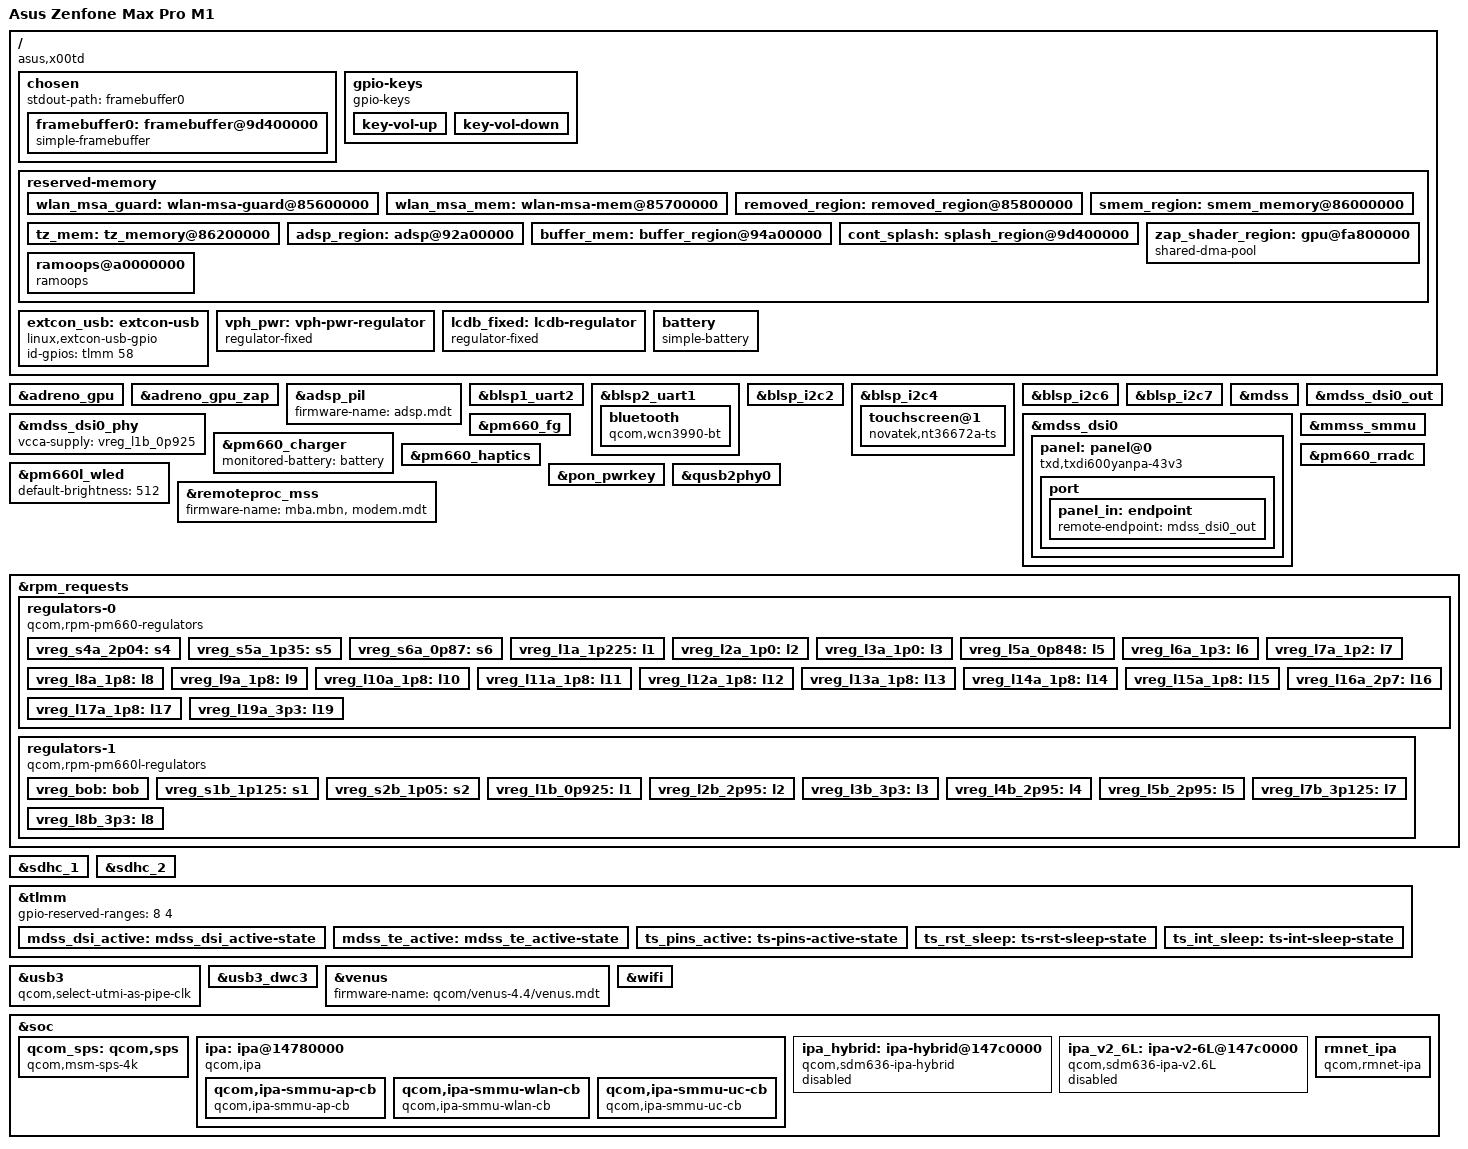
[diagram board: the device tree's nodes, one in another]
// SPDX-License-Identifier: GPL-2.0-only
/*
 * Copyright (c) 2022, Aboothahir U <aboothahirpkd@gmail.com>
 */

/dts-v1/;

#include "sdm636.dtsi"
#include "pm660.dtsi"
#include "pm660l.dtsi"
#include <dt-bindings/input/input.h>
#include <dt-bindings/input/gpio-keys.h>

/delete-node/ &qhee_code;
/delete-node/ &smem_region;
/delete-node/ &tz_mem;
/delete-node/ &adsp_region;
/delete-node/ &buffer_mem;
/delete-node/ &zap_shader_region;

/ {
	model = "Asus Zenfone Max Pro M1";
	compatible = "asus,x00td", "qcom,sdm636";
	chassis-type = "handset";

	qcom,msm-id = <0x159 0x0>;
	qcom,board-id = <0x1000b 0x0>;
	qcom,pmic-id = <0x1001b 0x101011a 0x0 0x0 0x1001b 0x201011a 0x0 0x0 0x1001b 0x102001a 0x0 0x0>;

	chosen {
		#address-cells = <2>;
		#size-cells = <2>;
		ranges;

		stdout-path = "framebuffer0";

		framebuffer0: framebuffer@9d400000 {
			compatible = "simple-framebuffer";
			reg = <0x0 0x9d400000 0x0 (1080 * 2160 * 4)>;
			status = "okay";
			width = <1080>;
			height = <2160>;
			stride = <(1080 * 4)>;
			format = "a8r8g8b8";
		};
	};

	gpio-keys {
		status = "okay";
		compatible = "gpio-keys";

		key-vol-up {
			label = "Volume Up";
			gpios = <&tlmm 44 GPIO_ACTIVE_LOW>;
			linux,input-type = <1>;
			linux,code = <KEY_VOLUMEUP>;
			wakeup-source;
			debounce-interval = <15>;
		};

		key-vol-down {
			label = "Volume Down";
			gpios = <&tlmm 43 GPIO_ACTIVE_LOW>;
			linux,input-type = <1>;
			linux,code = <KEY_VOLUMEDOWN>;
			wakeup-source;
			debounce-interval = <15>;
		};
	};

	reserved-memory {
		#address-cells = <2>;
		#size-cells = <2>;
		ranges;
		wlan_msa_guard: wlan-msa-guard@85600000 {
			reg = <0x0 0x85600000 0x0 0x100000>;
			no-map;
		};

		wlan_msa_mem: wlan-msa-mem@85700000 {
			reg = <0x0 0x85700000 0x0 0x100000>;
			no-map;
		};

		/* removed_regions in downstream / qhee_code */
		removed_region: removed_region@85800000 {
			reg = <0x0 0x85800000 0x0 0x600000>;
			no-map;
		};

		smem_region: smem_memory@86000000 {
			reg = <0x0 0x86000000 0x0 0x200000>;
			no-map;
		};

		/* tz_mem */
		tz_mem: tz_memory@86200000 {
			reg = <0x0 0x86200000 0x0 0x2D00000>;
			/* 0x86200000 + 0x2D00000 = 0x88F00000 */
			no-map;
		};

		/* adsp_fw_region */
		adsp_region: adsp@92a00000 {
			reg = <0x0 0x92a00000 0x0 0x1e00000>;
			no-map;
		};

		/* cdsp_fw_region */
		buffer_mem: buffer_region@94a00000 {
			reg = <0x0 0x94a00000 0x0 0x600000>;
			no-map;
		};

		/* cont_splash_region / framebuffer */
		cont_splash: splash_region@9d400000 {
			reg = <0x0 0x9d400000 0x0 0x2400000>;
			no-map;
		};

		zap_shader_region: gpu@fa800000 {
			compatible = "shared-dma-pool";
			reg = <0x0 0xfa800000 0x0 0x2000>;
			no-map;
		};

		ramoops@a0000000 {
			compatible = "ramoops";
			reg = <0x0 0xa0000000 0x0 0x400000>;
			console-size = <0x20000>;
			record-size = <0x20000>;
			ftrace-size = <0x0>;
			pmsg-size = <0x20000>;
		};
	};
	
	/*
	 * Until we hook up type-c detection, we
	 * have to stick with this. But it works.
	 */
	extcon_usb: extcon-usb {
		compatible = "linux,extcon-usb-gpio";
		id-gpios = <&tlmm 58 GPIO_ACTIVE_HIGH>;
	};

	vph_pwr: vph-pwr-regulator {
		compatible = "regulator-fixed";
		regulator-name = "vph_pwr";
		regulator-min-microvolt = <3700000>;
		regulator-max-microvolt = <3700000>;
		regulator-always-on;
		regulator-boot-on;
	};

	/*
	 * This is here until we have a driver for QPNP LCDB regulator.
	 * It can emulate both positive LDO and negative NCP supplies for panel.
	 */
	lcdb_fixed: lcdb-regulator {
		compatible = "regulator-fixed";
		regulator-name = "lcdb";
		/*
		 * Actual range for LCDB is 4.0 - 6.0V, but
		 * stock bootloader sets voltage to 5.4 V
		 */
		regulator-min-microvolt = <5400000>;
		regulator-max-microvolt = <5400000>;
		regulator-always-on;
		regulator-boot-on;
	};

	battery: battery {
			compatible = "simple-battery";

			charge-full-design-microamp-hours = <5000000>;
			voltage-min-design-microvolt = <3400000>;
			voltage-max-design-microvolt = <4350000>;
	};
};

&adreno_gpu {
	status = "okay";
};

&adreno_gpu_zap {
	memory-region = <&zap_shader_region>;
	firmware-name = "a512_zap.mbn";
};

&adsp_pil {
	firmware-name = "adsp.mdt";
};

&blsp1_uart2 {
	status = "okay";
};

&blsp2_uart1 {
	status = "okay";

	/* HCI Bluetooth */
	bluetooth {
		compatible = "qcom,wcn3990-bt";
		vddxo-supply = <&vreg_l9a_1p8>;
		vddrf-supply = <&vreg_l6a_1p3>;
		vddch0-supply = <&vreg_l19a_3p3>;
		vddio-supply = <&vreg_l13a_1p8>;
		max-speed = <3200000>;
	};
};

&blsp_i2c2 {
	status = "okay";
};

&blsp_i2c4 {
	#address-cells = <1>;
	#size-cells = <0>;

	status = "okay";

	touchscreen@1 {
		compatible = "novatek,nt36672a-ts";
		reg = <0x1>;
		iovcc-supply = <&vreg_l11a_1p8>;
		interrupts-extended = <&tlmm 67 IRQ_TYPE_EDGE_RISING>;
		pinctrl-names = "default", "sleep";
		pinctrl-0 = <&ts_pins_active>;
		pinctrl-1 = <&ts_int_sleep &ts_rst_sleep>;
		reset-gpios = <&tlmm 66 GPIO_ACTIVE_LOW>;
		touchscreen-size-x = <1080>;
		touchscreen-size-y = <2160>;
	};
};

&blsp_i2c6 {
	status = "okay";

	/* tfa98xx@34 */
};

&blsp_i2c7 { /* for P/L Sensor */
	status = "okay";
};

&mdss {
	status = "okay";
};

&mdss_dsi0 {
	status = "okay";

	#address-cells = <1>;
	#size-cells = <0>;

	vdd-supply = <&vreg_l1b_0p925>;
	vdda-supply = <&vreg_l1a_1p225>;

	panel: panel@0 {
		reg = <0>;
		compatible = "txd,txdi600yanpa-43v3", "novatek,nt36672a";

		vddio-supply = <&vreg_l11a_1p8>;
		vddneg-supply = <&lcdb_fixed>;
		vddpos-supply = <&lcdb_fixed>;

		backlight = <&pm660l_wled>;

		reset-gpios = <&tlmm 53 GPIO_ACTIVE_LOW>;

		pinctrl-names = "default";
		pinctrl-0 = <&mdss_dsi_active &mdss_te_active>;

		port {
			panel_in: endpoint {
				remote-endpoint = <&mdss_dsi0_out>;
			};
		};
	};
};

&mdss_dsi0_out {
	data-lanes = <0 1 2 3>;
	remote-endpoint = <&panel_in>;
};

&mdss_dsi0_phy {
	vcca-supply = <&vreg_l1b_0p925>;

	status = "okay";
};

&mmss_smmu {
	status = "okay";
};

&pm660_charger {
	monitored-battery = <&battery>;

	status = "okay";
};

&pm660_fg {
	monitored-battery = <&battery>;
	power-supplies = <&pm660_charger>;

	status = "okay";
};

&pm660_haptics {
	status = "okay";
};

&pm660_rradc {
	status = "okay";
};

&pm660l_wled {
	default-brightness = <512>;

	status = "okay";
};

&pon_pwrkey {
	status = "okay";
};

&qusb2phy0 {
	vdd-supply = <&vreg_l1b_0p925>;
	vdda-pll-supply = <&vreg_l10a_1p8>;
	vdda-phy-dpdm-supply = <&vreg_l7b_3p125>;

	status = "okay";
};

&remoteproc_mss {
	firmware-name = "mba.mbn", "modem.mdt";

	status = "okay";
};

&rpm_requests {
	regulators-0 {
		compatible = "qcom,rpm-pm660-regulators";

		vdd_s1-supply = <&vph_pwr>;
		vdd_s2-supply = <&vph_pwr>;
		vdd_s3-supply = <&vph_pwr>;
		vdd_s4-supply = <&vph_pwr>;
		vdd_s5-supply = <&vph_pwr>;
		vdd_s6-supply = <&vph_pwr>;

		vdd_l1_l6_l7-supply = <&vreg_s5a_1p35>;
		vdd_l2_l3-supply = <&vreg_s2b_1p05>;
		vdd_l5-supply = <&vreg_s2b_1p05>;
		vdd_l8_l9_l10_l11_l12_l13_l14-supply = <&vreg_s4a_2p04>;
		vdd_l15_l16_l17_l18_l19-supply = <&vreg_bob>;

		/*
		 * S1A (FTAPC0), S2A (FTAPC1), S3A (HFAPC1) are managed
		 * by the Core Power Reduction hardened (CPRh) and the
		 * Operating State Manager (OSM) HW automatically.
		 */

		vreg_s4a_2p04: s4 {
			regulator-min-microvolt = <1805000>;
			regulator-max-microvolt = <2040000>;
			regulator-enable-ramp-delay = <200>;
			regulator-always-on;
		};

		vreg_s5a_1p35: s5 {
			regulator-min-microvolt = <1224000>;
			regulator-max-microvolt = <1350000>;
			regulator-enable-ramp-delay = <200>;
		};

		vreg_s6a_0p87: s6 {
			regulator-min-microvolt = <504000>;
			regulator-max-microvolt = <992000>;
			regulator-enable-ramp-delay = <150>;
		};

		/* LDOs */
		vreg_l1a_1p225: l1 {
			regulator-min-microvolt = <1150000>;
			regulator-max-microvolt = <1250000>;
			regulator-enable-ramp-delay = <250>;
			regulator-allow-set-load;
		};

		vreg_l2a_1p0: l2 {
			regulator-min-microvolt = <950000>;
			regulator-max-microvolt = <1010000>;
			regulator-enable-ramp-delay = <250>;
		};

		vreg_l3a_1p0: l3 {
			regulator-min-microvolt = <950000>;
			regulator-max-microvolt = <1010000>;
			regulator-enable-ramp-delay = <250>;
		};

		vreg_l5a_0p848: l5 {
			regulator-min-microvolt = <525000>;
			regulator-max-microvolt = <950000>;
			regulator-enable-ramp-delay = <250>;
		};

		vreg_l6a_1p3: l6 {
			regulator-min-microvolt = <1200000>;
			regulator-max-microvolt = <1370000>;
			regulator-allow-set-load;
			regulator-enable-ramp-delay = <250>;
		};

		vreg_l7a_1p2: l7 {
			regulator-min-microvolt = <1200000>;
			regulator-max-microvolt = <1200000>;
			regulator-enable-ramp-delay = <250>;
            regulator-always-on;
		};

		vreg_l8a_1p8: l8 {
			regulator-min-microvolt = <1750000>;
			regulator-max-microvolt = <1800000>;
			regulator-enable-ramp-delay = <250>;
			regulator-system-load = <325000>;
			regulator-allow-set-load;
		};

		vreg_l9a_1p8: l9 {
			regulator-min-microvolt = <1750000>;
			regulator-max-microvolt = <1900000>;
			regulator-enable-ramp-delay = <250>;
			regulator-allow-set-load;
		};

		vreg_l10a_1p8: l10 {
			regulator-min-microvolt = <1780000>;
			regulator-max-microvolt = <1950000>;
			regulator-enable-ramp-delay = <250>;
			regulator-allow-set-load;
		};

		vreg_l11a_1p8: l11 {
			regulator-min-microvolt = <1780000>;
			regulator-max-microvolt = <1950000>;
			regulator-enable-ramp-delay = <250>;
		};

		vreg_l12a_1p8: l12 {
			regulator-min-microvolt = <1780000>;
			regulator-max-microvolt = <1950000>;
			regulator-enable-ramp-delay = <250>;
		};

		/* This gives power to the LPDDR4: never turn it off! */
		vreg_l13a_1p8: l13 {
			regulator-min-microvolt = <1780000>;
			regulator-max-microvolt = <1950000>;
			regulator-enable-ramp-delay = <250>;
			regulator-boot-on;
			regulator-always-on;
		};

		vreg_l14a_1p8: l14 {
			regulator-min-microvolt = <1710000>;
			regulator-max-microvolt = <1900000>;
			regulator-enable-ramp-delay = <250>;
		};

		vreg_l15a_1p8: l15 {
			regulator-min-microvolt = <1650000>;
			regulator-max-microvolt = <2950000>;
			regulator-enable-ramp-delay = <250>;
		};

		vreg_l16a_2p7: l16 {
			regulator-min-microvolt = <2800000>;
			regulator-max-microvolt = <2800000>;
			regulator-enable-ramp-delay = <250>;
			regulator-always-on;
		};

		vreg_l17a_1p8: l17 {
			regulator-min-microvolt = <1648000>;
			regulator-max-microvolt = <2952000>;
			regulator-enable-ramp-delay = <250>;
		};

		vreg_l19a_3p3: l19 {
			regulator-min-microvolt = <3312000>;
			regulator-max-microvolt = <3400000>;
			regulator-enable-ramp-delay = <250>;
			regulator-allow-set-load;
		};
	};

	regulators-1 {
		compatible = "qcom,rpm-pm660l-regulators";

		vdd_s1-supply = <&vph_pwr>;
		vdd_s2-supply = <&vph_pwr>;
		vdd_s3_s4-supply = <&vph_pwr>;
		vdd_s5-supply = <&vph_pwr>;
		vdd_s6-supply = <&vph_pwr>;

		vdd_l1_l9_l10-supply = <&vreg_s2b_1p05>;
		vdd_l2-supply = <&vreg_bob>;
		vdd_l3_l5_l7_l8-supply = <&vreg_bob>;
		vdd_l4_l6-supply = <&vreg_bob>;
		vdd_bob-supply = <&vph_pwr>;

		vreg_bob: bob {
			regulator-min-microvolt = <3300000>;
			regulator-max-microvolt = <3600000>;
			regulator-enable-ramp-delay = <500>;
		};

		vreg_s1b_1p125: s1 {
			regulator-min-microvolt = <1125000>;
			regulator-max-microvolt = <1125000>;
			regulator-enable-ramp-delay = <200>;
		};

		vreg_s2b_1p05: s2 {
			regulator-min-microvolt = <1050000>;
			regulator-max-microvolt = <1050000>;
			regulator-enable-ramp-delay = <200>;
		};

		/* LDOs */
		vreg_l1b_0p925: l1 {
			regulator-min-microvolt = <800000>;
			regulator-max-microvolt = <925000>;
			regulator-enable-ramp-delay = <250>;
			regulator-allow-set-load;
		};

		/* SDHCI 3.3V signal doesn't seem to be supported. */
		vreg_l2b_2p95: l2 {
			regulator-min-microvolt = <1648000>;
			regulator-max-microvolt = <3100000>;
			regulator-enable-ramp-delay = <250>;
			regulator-allow-set-load;
		};

		vreg_l3b_3p3: l3 {
			regulator-min-microvolt = <1700000>;
			regulator-max-microvolt = <3300000>;
			regulator-enable-ramp-delay = <250>;
			regulator-allow-set-load;
			regulator-always-on;
		};

		vreg_l4b_2p95: l4 {
			regulator-min-microvolt = <2944000>;
			regulator-max-microvolt = <2952000>;
			regulator-enable-ramp-delay = <250>;

			regulator-min-microamp = <200>;
			regulator-max-microamp = <600000>;
			regulator-system-load = <570000>;
			regulator-allow-set-load;
		};

		/*
		 * Downstream specifies a range of 1721-3600mV,
		 * but the only assigned consumers are SDHCI2 VMMC
		 * and Coresight QPDI that both request pinned 2.95V.
		 * Tighten the range to 1.8-3.328 (closest to 3.3) to
		 * make the mmc driver happy.
		 */
		vreg_l5b_2p95: l5 {
			regulator-min-microvolt = <1800000>;
			regulator-max-microvolt = <3328000>;
			regulator-enable-ramp-delay = <250>;
			regulator-allow-set-load;
		};

		vreg_l7b_3p125: l7 {
			regulator-min-microvolt = <2700000>;
			regulator-max-microvolt = <3125000>;
			regulator-enable-ramp-delay = <250>;
		};

		vreg_l8b_3p3: l8 {
			regulator-min-microvolt = <3200000>;
			regulator-max-microvolt = <3400000>;
			regulator-enable-ramp-delay = <250>;
		};
	};
};

&sdhc_1 {
	bus-width = <8>;
	non-removable;
	mmc-ddr-1_8v;    
	mmc-hs200-1_8v;  
	mmc-hs400-1_8v; 
	vmmc-supply = <&vreg_l4b_2p95>;
	vqmmc-supply = <&vreg_l8a_1p8>;

	status = "okay";
};


&sdhc_2 {
	cd-gpios = <&tlmm 54 GPIO_ACTIVE_HIGH>;

	vmmc-supply = <&vreg_l5b_2p95>;
	vqmmc-supply = <&vreg_l2b_2p95>;

	status = "okay";
};

&tlmm {
	gpio-reserved-ranges = <8 4>;

	mdss_dsi_active: mdss_dsi_active-state {
		function = "gpio";
		pins = "gpio53";
		drive-strength = <8>;
		bias-disable;
	};

	mdss_te_active: mdss_te_active-state {
		pins = "gpio59";
		function = "mdp_vsync";
		drive-strength = <2>;
		bias-pull-down;
	};

	ts_pins_active: ts-pins-active-state {
		pins = "gpio66", "gpio67";
		function = "gpio";
		drive-strength = <16>;
		bias-pull-up;
	};

	ts_rst_sleep: ts-rst-sleep-state {
		pins = "gpio66";
		function = "gpio";
		drive-strength = <2>;
		bias-pull-down;
	};

	ts_int_sleep: ts-int-sleep-state {
		pins = "gpio67";
		function = "gpio";
		drive-strength = <2>;
		bias-disable;
	};
};

&usb3 {
	qcom,select-utmi-as-pipe-clk;

	status = "okay";
};

&usb3_dwc3 {
	dr_mode = "peripheral";
	extcon = <&extcon_usb>;

	maximum-speed = "high-speed";
	phys = <&qusb2phy0>;
	phy-names = "usb2-phy";

	status = "okay";
};

&venus {
	firmware-name = "qcom/venus-4.4/venus.mdt";

	status = "okay";
};

&wifi {
	vdd-1.8-xo-supply = <&vreg_l9a_1p8>;
	vdd-1.3-rfa-supply = <&vreg_l6a_1p3>;
	vdd-3.3-ch0-supply = <&vreg_l19a_3p3>;

	status = "okay";
};

&soc {
    qcom_sps: qcom,sps {
		compatible = "qcom,msm-sps-4k";
		qcom,device-type = <3>;     /* default value — no BAMDMA */
		qcom,pipe-attr-ee;
		status = "okay";
	};

	/* IPA hardware (chip core + BAM-DMA at +0x4000) */
	ipa: ipa@14780000 {
		compatible = "qcom,ipa";

		/* Two separate register ranges: IPA core + BAM-DMA */
		reg = <0x14780000 0x4000>,
		      <0x14784000 0x3C000>;
		reg-names = "ipa-base", "bam-base";

		qcom,ipa-hw-ver = <6>;
		qcom,ipa-hw-mode = <0>;            /* IPA_MODE_NORMAL */
		qcom,ee = <0>;
		qcom,wan-rx-ring-size = <0xc0>;    /* matches Android 4.19 */
		qcom,lan-rx-ring-size = <0xc0>;
		qcom,rx-polling-sleep-ms = <1>;
		qcom,ipa-polling-iteration = <40>;
		/* __ipa_arm_smmu_patch__ - required for SMMU CB child node probe */
		qcom,arm-smmu;
		qcom,smmu-s1-bypass;
		qcom,smmu-disable-htw;
		qcom,modem-cfg-emb-pipe-flt;        /* CRITICAL: modem handles internal filter install */
		qcom,use-dma-zone;                   /* DMA-capable mem for descriptors */
		qcom,use-ipa-tethering-bridge;       /* tethering paths */
		qcom,ipa-wdi2;                       /* WDI 2.0 capability advertise */
		/* IPA_HW_v2_6L */

		/* Routing/pipe configuration from MASTER V7 vendor config */
		qcom,pipe-wan = <5>;
		qcom,rt-idx-wan = <8>;
		qcom,rt-idx-default = <7>;

		interrupts = <GIC_SPI 333 IRQ_TYPE_LEVEL_HIGH>,    /* IPA - matches Android (was EDGE_RISING) */
			     <GIC_SPI 432 IRQ_TYPE_LEVEL_HIGH>;     /* BAM */
		interrupt-names = "ipa-irq", "bam-irq";

		clocks = <&rpmcc RPM_SMD_IPA_CLK>,
			 <&rpmcc RPM_SMD_AGGR2_NOC_CLK>;
		clock-names = "core_clk", "smmu_clk";

        /* Force RPM clock vote at probe time regardless of driver bugs */
        assigned-clocks = <&rpmcc RPM_SMD_IPA_CLK>;
        assigned-clock-rates = <200000000>;       /* 200 MHz turbo */

		/* SMMU stream IDs for the IPA core itself */
		iommus = <&anoc2_smmu 0x19C0>,
			 <&anoc2_smmu 0x19C2>;

		dma-coherent;

		/* Bus interconnects (mainline-style; vendor 4.19 driver
		 * ignores these but they don't hurt) */
		interconnects = <&a2noc MASTER_IPA &bimc SLAVE_EBI>,
				<&a2noc MASTER_IPA &snoc SLAVE_IMEM>,
				<&gnoc MASTER_APSS_PROC &snoc SLAVE_IPA>;
		interconnect-names = "ipa-mem", "ipa-imem", "cpu-cfg";

		modem-remoteproc = <&remoteproc_mss>;

		status = "okay";	/* Phase 4g: hybrid takes over */

		/* Children: SMMU context banks parsed by ipa_smmu_*_cb_probe() */
		qcom,ipa-smmu-ap-cb {
			compatible = "qcom,ipa-smmu-ap-cb";
			iommus = <&anoc2_smmu 0x19C0>;
			qcom,iova-mapping = <0x20000000 0x40000000>;
		};

		qcom,ipa-smmu-wlan-cb {
			compatible = "qcom,ipa-smmu-wlan-cb";
			iommus = <&anoc2_smmu 0x19C1>;
			qcom,iova-mapping = <0x20000000 0x40000000>;
		};

		qcom,ipa-smmu-uc-cb {
			compatible = "qcom,ipa-smmu-uc-cb";
			iommus = <&anoc2_smmu 0x19C2>;
			qcom,iova-mapping = <0x20000000 0x40000000>;
		};
	};

	/* Hybrid IPA driver — mainline drivers/net/ipa/ structure layered
	 * over the SPS/BAM backend ported from the 4.19 vendor source.
	 *
	 * Disabled by default. To test the hybrid driver, flip the
	 * status on three nodes:
	 *   1. Vendor "ipa: ipa@14780000" above      → "disabled"
	 *   2. This node "ipa_hybrid: ipa-hybrid..." → "okay"
	 *   3. Vendor "rmnet_ipa" below              → "disabled"
	 * Then build with CONFIG_QCOM_IPA_V2_HYBRID=m and the
	 * corresponding CONFIG_QCOM_IPA_V2 (vendor) unset.
	 *
	 * The hybrid driver creates its rmnet netdev internally via
	 * mainline ipa_modem.c — no separate rmnet_ipa DT node needed.
	 *
	 * Note on reg-names: mainline expects three named MMIO regions
	 * ("ipa-reg", "ipa-shared", "bam-base") whereas the vendor port
	 * exposes only two ("ipa-base", "bam-base").
	 *
	 * Vendor maps a single "ipa-base" 0x14780000 / 0x4effc covering the
	 * whole IPA wrapper, then internally does mmio = ioremap(base +
	 * IPA_REG_BASE_OFST_v2_5, ...) = 0x147c0000. All vendor IPA_*_OFST
	 * register offsets are relative to that 0x147c0000 base.
	 *
	 * The mainline-style "ipa-reg" region must therefore sit at the
	 * register-block base (0x147c0000), not at the wrapper start. SRAM
	 * lives inside the wrapper at 0x14785000 (vendor IPA_SRAM_SW_FIRST
	 * = 0x5000 from wrapper) and BAM at 0x14784000.
	 *
	 * Pre-Phase-3a a faulty <0x14780000 0x5000> mapping caused every
	 * placeholder-reg write to land in the wrapper instead of the
	 * register block, hitting a reset/control register and hard-
	 * powering off the SoC. See Phase 4g fix #13.
	 */
	ipa_hybrid: ipa-hybrid@147c0000 {
		compatible = "qcom,sdm636-ipa-hybrid";
		status = "disabled";	/* Phase 4g: first boot test */

		reg = <0x147c0000 0xf000>,
		      <0x14785000 0x4000>,
		      <0x14784000 0x3C000>;
		reg-names = "ipa-reg", "ipa-shared", "bam-base";

		/* "ipa-shared" size: v2.6L SRAM partition layout (see
		 * include/ipa_ram_mmap.h IPA_MEM_v2_6L_RAM_END_OFST) ends
		 * at 0x1df8 ≈ 7.5 KB. We map 16 KB (0x4000) to allow head-
		 * room and match common v2.x SoC SRAM sizes. The first
		 * earlier 4 KB sizing caused ipa_mem_size_valid() to reject
		 * IPA_MEM_MODEM (size 6376) as ending beyond the limit.
		 */

		interrupts = <GIC_SPI 333 IRQ_TYPE_LEVEL_HIGH>,
			     <GIC_SPI 432 IRQ_TYPE_LEVEL_HIGH>;
		interrupt-names = "ipa", "bam";

		/* Mainline IPA expects four interrupt-names ("ipa-setup-ready",
		 * "ipa-clock-query") and a "ipa-clock-enabled*" smem-state pair
		 * to handle modem readiness signaling. X00TD modem firmware
		 * doesn't speak that protocol (it predates SDM845's mainline
		 * IPA conventions). Sharing the standard "ready" bit
		 * (modem_smp2p_in 1) with remoteproc_mss fails IRQ-flag
		 * compatibility — q6v5 ready is requested IRQF_ONESHOT,
		 * ipa-setup-ready is not, and neither asks for IRQF_SHARED.
		 *
		 * Instead of fighting that, we leave SMP2P wiring out and let
		 * ipa_smp2p_init() soft-fail (fix #12). ipa_modem.c hooks the
		 * QCOM_SSR_AFTER_POWERUP event from the existing mpss SSR
		 * notifier to trigger ipa_setup() — same effective lifecycle
		 * signal as ipa-setup-ready, no IRQ contention.
		 */

		clocks = <&rpmcc RPM_SMD_IPA_CLK>;
		clock-names = "core";

		iommus = <&anoc2_smmu 0x19C0>,
			 <&anoc2_smmu 0x19C2>;

		interconnects = <&a2noc MASTER_IPA &bimc SLAVE_EBI>,
				<&a2noc MASTER_IPA &snoc SLAVE_IMEM>,
				<&gnoc MASTER_APSS_PROC &snoc SLAVE_IPA>;
		interconnect-names = "ipa-mem", "ipa-imem", "cpu-cfg";

		modem-remoteproc = <&remoteproc_mss>;
		modem-init;
	};

	/* Mainline-style clean-room IPA v2.6L driver — drivers/net/ipa_v2_6L/
	 *
	 * Built fresh in 2026-05-22 based on:
	 *   - vendor 4.19 register sequences (trace/*.log sondas)
	 *   - ipa2-lite BAM access pattern (proven 2G cellular DL)
	 *   - mainline ipa.ko file-structure conventions
	 *
	 * Coexists with the legacy "ipa_hybrid" node — only one of the
	 * three IPA nodes (ipa, ipa_hybrid, ipa_v2_6L) can be status="okay"
	 * at a time because they share the same hardware MMIO region.
	 *
	 * To test ipa_v2_6L on X00TD:
	 *   1. ipa_hybrid status = "disabled"
	 *   2. ipa_v2_6L  status = "okay"
	 *   3. rmnet_ipa  status = "disabled"
	 *   4. CONFIG_IPA_V2_6L=m (or =y) in kernel config
	 *
	 * Identical reg/IRQ map to ipa_hybrid above — same SoC, same HW.
	 * Different reg-names: we use "bam-base" instead of "bam-reg" for
	 * convention parity with hybrid.
	 */
	ipa_v2_6L: ipa-v2-6L@147c0000 {
		compatible = "qcom,sdm636-ipa-v2.6L";
		status = "disabled";	/* enable to switch from hybrid */

		/* SRAM DIRECT_ACCESS lives at:
		 *   wrapper(0x14780000) + IPA_REG_BASE(0x40000) +
		 *   IPA_SRAM_DIRECT_ACCESS_N_OFST_v2_0(0)(0x5000)
		 *   = 0x147c5000
		 *
		 * Hybrid's DTS uses 0x14785000 = wrapper + 0x5000, which is
		 * actually inside BAM register space (BAM_REVISION area at
		 * BAM_REG(0x1000) = 0x14784000+0x1000 = 0x14785000). Hybrid
		 * works despite this because mainline ipa.ko reads SRAM only
		 * via IPA_CMD_DMA_SHARED_MEM (reverse direction), never
		 * through the direct-access MMIO window.
		 *
		 * Our driver does ioread32 from the SRAM window for debugfs
		 * dumps, so we need the correct physical address. Verified
		 * via vendor 4.19 ipa_v2/ipa_reg.h:
		 *   IPA_REG_BASE_OFST_v2_5         = 0x00040000
		 *   IPA_SRAM_DIRECT_ACCESS_N_OFST_v2_0(0) = 0x00005000
		 *
		 * 0x147c5000+0x4000 falls inside ipa-reg's 0x147c0000+0xf000
		 * range. The overlap is handled by devm_ioremap() (no resource
		 * reservation) — they are two functional views of the same
		 * MMIO area.
		 */
		reg = <0x147c0000 0xf000>,
		      <0x14784000 0x3C000>,
		      <0x147c5000 0x4000>;
		reg-names = "ipa-reg", "bam-base", "ipa-shared";

		interrupts = <GIC_SPI 333 IRQ_TYPE_LEVEL_HIGH>,
			     <GIC_SPI 432 IRQ_TYPE_LEVEL_HIGH>;
		interrupt-names = "ipa", "bam";

		clocks = <&rpmcc RPM_SMD_IPA_CLK>;
		clock-names = "core";

		iommus = <&anoc2_smmu 0x19C0>,
			 <&anoc2_smmu 0x19C2>;

		interconnects = <&a2noc MASTER_IPA &bimc SLAVE_EBI>,
				<&a2noc MASTER_IPA &snoc SLAVE_IMEM>,
				<&gnoc MASTER_APSS_PROC &snoc SLAVE_IPA>;
		interconnect-names = "ipa-mem", "ipa-imem", "cpu-cfg";

		modem-remoteproc = <&remoteproc_mss>;
	};

	/* RMNET netdev driver — used ONLY by the vendor 4.19 IPA port.
	 *
	 * drivers/platform/msm/ipa/ipa_v2/rmnet_ipa.c is a separate
	 * platform driver matching "qcom,rmnet-ipa" that builds the
	 * rmnet_ipa0 netdev. The mainline-style hybrid driver instead
	 * creates the same netdev internally from ipa_modem.c during
	 * its main IPA probe; for hybrid testing this node should be
	 * status = "disabled".
	 *
	 * Required ON when the vendor IPA node (ipa@14780000) is active.
	 */
	rmnet_ipa {
		compatible = "qcom,rmnet-ipa";
		/* __rmnet_ipa_dt_patch__ - properties from 4.19 vendor analysis */
		qcom,rmnet-ipa-ssr;             /* enable MPSS POWERUP handshake */
		qcom,ipa-loaduC;                /* load uC firmware */
		qcom,ipa-advertise-sg-support;  /* scatter-gather support */
		qcom,ipa-napi-enable;           /* enable NAPI on pipe 5 (RX) */
		qcom,wan-rx-desc-size = <1024>;
		status = "okay";	/* Phase 4g: hybrid handles rmnet internally */
	};
};
